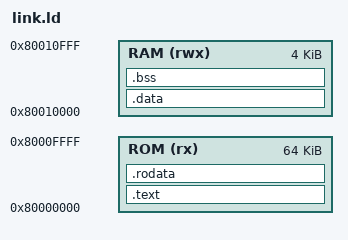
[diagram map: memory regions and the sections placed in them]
OUTPUT_ARCH("riscv")
ENTRY(_start)

MEMORY
{
    ROM (rx)  : ORIGIN = 0x80000000, LENGTH = 64K
    RAM (rwx) : ORIGIN = 0x80010000, LENGTH = 4K
}

SECTIONS
{
    .text : {
        KEEP(*(.text.init))
        *(.text .text.*)
        . = ALIGN(4);
    } > ROM

    .rodata : {
        *(.rodata .rodata.* .srodata .srodata.*)
        . = ALIGN(4);
    } > ROM

    /* Local C variables go to the Stack (RAM). Global constants stay in ROM. */
    .data : {
        *(.data .data.* .sdata .sdata.*)
        . = ALIGN(4);
    } > RAM

    . = ALIGN(16);
    __global_pointer$ = . + 0x800;

    .bss : {
        __bss_start = .;
        *(.bss .bss.* .sbss .sbss.* COMMON)
        . = ALIGN(4);
        __bss_end = .;
    } > RAM

    __stack_top = ORIGIN(RAM) + LENGTH(RAM);
}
